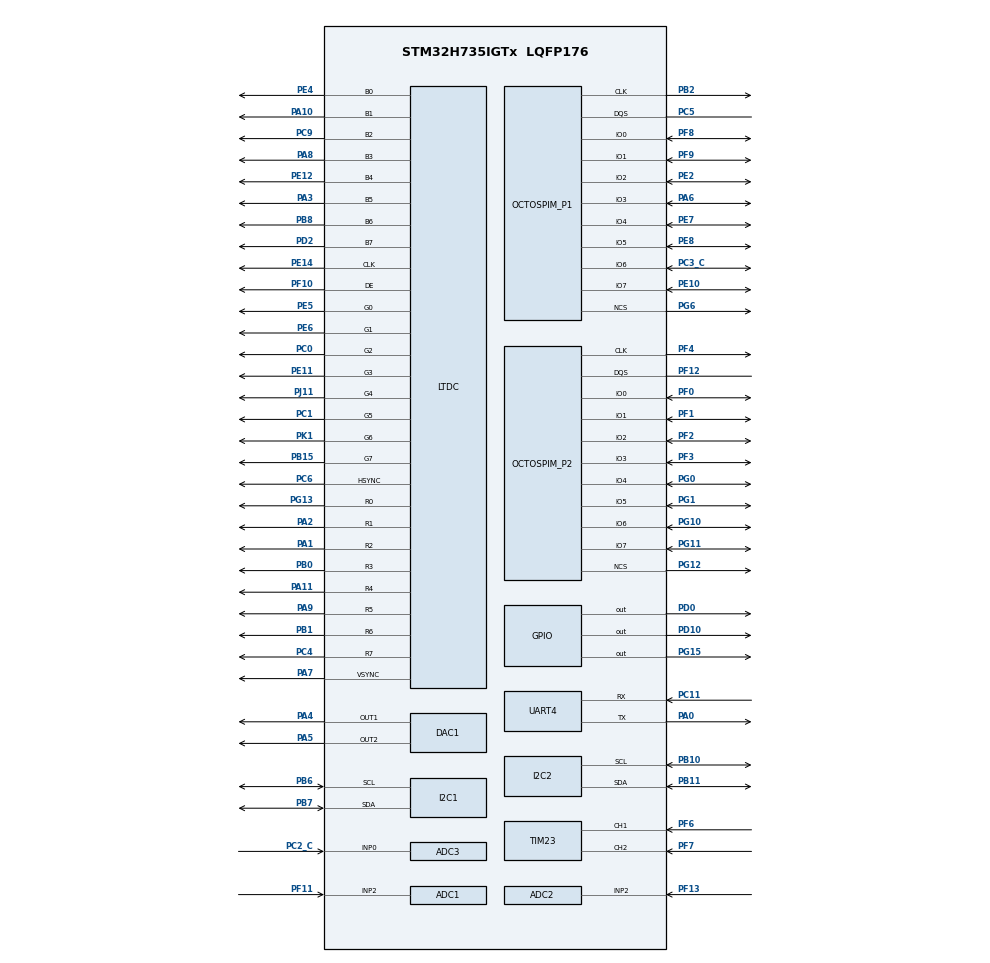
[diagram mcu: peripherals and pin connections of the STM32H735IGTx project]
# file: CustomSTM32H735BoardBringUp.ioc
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ADC1.Channel-0\#ChannelRegularConversion=ADC_CHANNEL_2
ADC1.ClockPrescaler=ADC_CLOCK_ASYNC_DIV4
ADC1.NbrOfConversionFlag=1
ADC1.OffsetNumber-0\#ChannelRegularConversion=ADC_OFFSET_NONE
ADC1.OffsetSignedSaturation-0\#ChannelRegularConversion=DISABLE
ADC1.Rank-0\#ChannelRegularConversion=1
ADC1.SamplingTime-0\#ChannelRegularConversion=ADC_SAMPLETIME_1CYCLE_5
ADC1.master=1
ADC2.Channel-0\#ChannelRegularConversion=ADC_CHANNEL_2
ADC2.ClockPrescaler=ADC_CLOCK_ASYNC_DIV4
ADC2.NbrOfConversionFlag=1
ADC2.OffsetNumber-0\#ChannelRegularConversion=ADC_OFFSET_NONE
ADC2.OffsetSignedSaturation-0\#ChannelRegularConversion=DISABLE
ADC2.Rank-0\#ChannelRegularConversion=1
ADC2.SamplingTime-0\#ChannelRegularConversion=ADC_SAMPLETIME_1CYCLE_5
ADC3.Channel-0\#ChannelRegularConversion=ADC_CHANNEL_0
ADC3.ClockPrescaler=ADC_CLOCK_ASYNC_DIV4
ADC3.NbrOfConversionFlag=1
ADC3.OffsetNumber-0\#ChannelRegularConversion=ADC_OFFSET_NONE
ADC3.OffsetSign-0\#ChannelRegularConversion=ADC3_OFFSET_SIGN_NEGATIVE
ADC3.Rank-0\#ChannelRegularConversion=1
ADC3.SamplingTime-0\#ChannelRegularConversion=ADC3_SAMPLETIME_2CYCLES_5
CORTEX_M7.AccessPermission-Cortex_Memory_Protection_Unit_Region0_Settings=MPU_REGION_FULL_ACCESS
CORTEX_M7.AccessPermission-Cortex_Memory_Protection_Unit_Region2_Settings=MPU_REGION_FULL_ACCESS
CORTEX_M7.AccessPermission-Cortex_Memory_Protection_Unit_Region4_Settings=MPU_REGION_FULL_ACCESS
CORTEX_M7.BaseAddress-Cortex_Memory_Protection_Unit_Region0_Settings=0x24000000
CORTEX_M7.BaseAddress-Cortex_Memory_Protection_Unit_Region1_Settings=0x70000000
CORTEX_M7.BaseAddress-Cortex_Memory_Protection_Unit_Region2_Settings=0x70000000
CORTEX_M7.BaseAddress-Cortex_Memory_Protection_Unit_Region3_Settings=0x90000000
CORTEX_M7.BaseAddress-Cortex_Memory_Protection_Unit_Region4_Settings=0x90000000
CORTEX_M7.CPU_DCache=Enabled
CORTEX_M7.CPU_ICache=Enabled
CORTEX_M7.DisableExec-Cortex_Memory_Protection_Unit_Region0_Settings=MPU_INSTRUCTION_ACCESS_DISABLE
CORTEX_M7.DisableExec-Cortex_Memory_Protection_Unit_Region1_Settings=MPU_INSTRUCTION_ACCESS_DISABLE
CORTEX_M7.DisableExec-Cortex_Memory_Protection_Unit_Region2_Settings=MPU_INSTRUCTION_ACCESS_DISABLE
CORTEX_M7.DisableExec-Cortex_Memory_Protection_Unit_Region3_Settings=MPU_INSTRUCTION_ACCESS_DISABLE
CORTEX_M7.DisableExec-Cortex_Memory_Protection_Unit_Region4_Settings=MPU_INSTRUCTION_ACCESS_DISABLE
CORTEX_M7.Enable-Cortex_Memory_Protection_Unit_Region0_Settings=MPU_REGION_ENABLE
CORTEX_M7.Enable-Cortex_Memory_Protection_Unit_Region1_Settings=MPU_REGION_ENABLE
CORTEX_M7.Enable-Cortex_Memory_Protection_Unit_Region2_Settings=MPU_REGION_ENABLE
CORTEX_M7.Enable-Cortex_Memory_Protection_Unit_Region3_Settings=MPU_REGION_ENABLE
CORTEX_M7.Enable-Cortex_Memory_Protection_Unit_Region4_Settings=MPU_REGION_ENABLE
CORTEX_M7.IsBufferable-Cortex_Memory_Protection_Unit_Region0_Settings=MPU_ACCESS_BUFFERABLE
CORTEX_M7.IsBufferable-Cortex_Memory_Protection_Unit_Region2_Settings=MPU_ACCESS_BUFFERABLE
CORTEX_M7.IsBufferable-Cortex_Memory_Protection_Unit_Region4_Settings=MPU_ACCESS_NOT_BUFFERABLE
CORTEX_M7.IsCacheable-Cortex_Memory_Protection_Unit_Region0_Settings=MPU_ACCESS_CACHEABLE
CORTEX_M7.IsCacheable-Cortex_Memory_Protection_Unit_Region2_Settings=MPU_ACCESS_CACHEABLE
CORTEX_M7.IsCacheable-Cortex_Memory_Protection_Unit_Region4_Settings=MPU_ACCESS_CACHEABLE
CORTEX_M7.MPU_Control=MPU_PRIVILEGED_DEFAULT
CORTEX_M7.Size-Cortex_Memory_Protection_Unit_Region0_Settings=MPU_REGION_SIZE_512KB
CORTEX_M7.Size-Cortex_Memory_Protection_Unit_Region1_Settings=MPU_REGION_SIZE_512MB
CORTEX_M7.Size-Cortex_Memory_Protection_Unit_Region2_Settings=MPU_REGION_SIZE_8MB
CORTEX_M7.Size-Cortex_Memory_Protection_Unit_Region3_Settings=MPU_REGION_SIZE_512MB
CORTEX_M7.Size-Cortex_Memory_Protection_Unit_Region4_Settings=MPU_REGION_SIZE_64MB
CORTEX_M7.default_mode_Activation=0
DAC1.DAC_Channel-DAC_OUT1=DAC_CHANNEL_1
DAC1.DAC_Channel-DAC_OUT2=DAC_CHANNEL_2
DMA2D.ColorMode=DMA2D_OUTPUT_RGB888
DMA2D.Mode=DMA2D_R2M
FREERTOS.Tasks01=defaultTask,24,1024,StartDefaultTask,Default,NULL,Dynamic,NULL,NULL;myTask02,8,1024,StartTask02,Default,NULL,Dynamic,NULL,NULL;TouchGFXTask,24,10000,TouchGFX_Task,As external,NULL,Dynamic,NULL,NULL
FREERTOS.configTOTAL_HEAP_SIZE=200000
FREERTOS.configUSE_NEWLIB_REENTRANT=1
I2C1.Timing=0x60404E72
I2C2.Timing=0x60404E72
LTDC.ActiveH=272
LTDC.ActiveW=480
LTDC.Alpha_L0=255
LTDC.FBStartAdress_L0=0x70000000
LTDC.HBP=13
LTDC.HFP=32
LTDC.HSync=41
LTDC.ImageHeight_L0=272
LTDC.ImageWidth_L0=480
LTDC.Layers=0
LTDC.PixelFormat_L0=LTDC_PIXEL_FORMAT_RGB888
LTDC.VSync=10
LTDC.WindowX1_L0=480
LTDC.WindowY1_L0=272
Mcu.Family=STM32H7
Mcu.Name=STM32H735IGTx
Mcu.Package=LQFP176
NVIC.LTDC_IRQn=true\:5\:0\:false\:false\:true\:true\:true\:true\:true
NVIC.PriorityGroup=NVIC_PRIORITYGROUP_4
NVIC.TIM6_DAC_IRQn=true\:15\:0\:false\:false\:true\:false\:false\:true\:true
NVIC.TimeBase=TIM6_DAC_IRQn
NVIC.TimeBaseIP=TIM6
OCTOSPI1.ChipSelectHighTime=2
OCTOSPI1.ClockPrescaler=2
OCTOSPI1.FifoThreshold=4
OCTOSPI1.MemoryType=HAL_OSPI_MEMTYPE_MACRONIX
OCTOSPI2.AccessTime=6
OCTOSPI2.ChipSelectBoundary=23
OCTOSPI2.ChipSelectHighTime=4
OCTOSPI2.ClockPrescaler=2
OCTOSPI2.DelayBlockBypass=HAL_OSPI_DELAY_BLOCK_USED
OCTOSPI2.DelayHoldQuarterCycle=HAL_OSPI_DHQC_ENABLE
OCTOSPI2.DeviceSize=24
OCTOSPI2.FifoThreshold=4
OCTOSPI2.LatencyMode=HAL_OSPI_FIXED_LATENCY
OCTOSPI2.RWRecoveryTime=3
OCTOSPI2.Refresh=400
OCTOSPI2.WriteZeroLatency=HAL_OSPI_LATENCY_ON_WRITE
PA0.Mode=Asynchronous
PA0.Signal=UART4_TX
PA1.Mode=RGB888
PA1.Signal=LTDC_R2
PA10.Mode=RGB888
PA10.Signal=LTDC_B1
PA11.Mode=RGB888
PA11.Signal=LTDC_R4
PA13(JTMS/SWDIO).Mode=Serial_Wire
PA13(JTMS/SWDIO).Signal=DEBUG_JTMS-SWDIO
PA14(JTCK/SWCLK).Mode=Serial_Wire
PA14(JTCK/SWCLK).Signal=DEBUG_JTCK-SWCLK
PA2.Mode=RGB888
PA2.Signal=LTDC_R1
PA3.Mode=RGB888
PA3.Signal=LTDC_B5
PA4.Signal=COMP_DAC11_group
PA5.Signal=COMP_DAC12_group
PA6.Mode=OCTOSPI1_IOL_Port1L
PA6.Signal=OCTOSPIM_P1_IO3
PA7.Mode=RGB888
PA7.Signal=LTDC_VSYNC
PA8.Mode=RGB888
PA8.Signal=LTDC_B3
PA9.Mode=RGB888
PA9.Signal=LTDC_R5
PB0.Mode=RGB888
PB0.Signal=LTDC_R3
PB1.Mode=RGB888
PB1.Signal=LTDC_R6
PB10.Mode=I2C
PB10.Signal=I2C2_SCL
PB11.Mode=I2C
PB11.Signal=I2C2_SDA
PB15.Mode=RGB888
PB15.Signal=LTDC_G7
PB2.Mode=O1_P1_CLK
PB2.Signal=OCTOSPIM_P1_CLK
PB6.Mode=I2C
PB6.Signal=I2C1_SCL
PB7.Mode=I2C
PB7.Signal=I2C1_SDA
PB8.Mode=RGB888
PB8.Signal=LTDC_B6
PC0.Mode=RGB888
PC0.Signal=LTDC_G2
PC1.Mode=RGB888
PC1.Signal=LTDC_G5
PC11.Mode=Asynchronous
PC11.Signal=UART4_RX
PC2_C.Mode=IN0-Single-Ended
PC2_C.Signal=ADC3_INP0
PC3_C.Mode=OCTOSPI1_IOH_Port1H
PC3_C.Signal=OCTOSPIM_P1_IO6
PC4.Mode=RGB888
PC4.Signal=LTDC_R7
PC5.Mode=OCTOSPI1_Port1_DQS
PC5.Signal=OCTOSPIM_P1_DQS
PC6.Mode=RGB888
PC6.Signal=LTDC_HSYNC
PC9.Mode=RGB888
PC9.Signal=LTDC_B2
PD0.Signal=GPIO_Output
PD10.Signal=GPIO_Output
PD2.Mode=RGB888
PD2.Signal=LTDC_B7
PE10.Mode=OCTOSPI1_IOH_Port1H
PE10.Signal=OCTOSPIM_P1_IO7
PE11.Mode=RGB888
PE11.Signal=LTDC_G3
PE12.Mode=RGB888
PE12.Signal=LTDC_B4
PE14.Mode=RGB888
PE14.Signal=LTDC_CLK
PE2.Mode=OCTOSPI1_IOL_Port1L
PE2.Signal=OCTOSPIM_P1_IO2
PE4.Mode=RGB888
PE4.Signal=LTDC_B0
PE5.Mode=RGB888
PE5.Signal=LTDC_G0
PE6.Mode=RGB888
PE6.Signal=LTDC_G1
PE7.Mode=OCTOSPI1_IOH_Port1H
PE7.Signal=OCTOSPIM_P1_IO4
PE8.Mode=OCTOSPI1_IOH_Port1H
PE8.Signal=OCTOSPIM_P1_IO5
PF0.Mode=OCTOSPI2_IOL_Port2L
PF0.Signal=OCTOSPIM_P2_IO0
PF1.Mode=OCTOSPI2_IOL_Port2L
PF1.Signal=OCTOSPIM_P2_IO1
PF10.Mode=RGB888
PF10.Signal=LTDC_DE
PF11.Mode=IN2-Single-Ended
PF11.Signal=ADC1_INP2
PF12.Mode=OCTOSPI2_Port2_DQS
PF12.Signal=OCTOSPIM_P2_DQS
PF13.Mode=IN2-Single-Ended
PF13.Signal=ADC2_INP2
PF2.Mode=OCTOSPI2_IOL_Port2L
PF2.Signal=OCTOSPIM_P2_IO2
PF3.Mode=OCTOSPI2_IOL_Port2L
PF3.Signal=OCTOSPIM_P2_IO3
PF4.Mode=O2_P2_CLK
PF4.Signal=OCTOSPIM_P2_CLK
PF6.Mode=Encoder_Interface
PF6.Signal=TIM23_CH1
PF7.Signal=S_TIM23_CH2
PF8.Mode=OCTOSPI1_IOL_Port1L
PF8.Signal=OCTOSPIM_P1_IO0
PF9.Mode=OCTOSPI1_IOL_Port1L
PF9.Signal=OCTOSPIM_P1_IO1
PG0.Mode=OCTOSPI2_IOH_Port2H
PG0.Signal=OCTOSPIM_P2_IO4
PG1.Mode=OCTOSPI2_IOH_Port2H
PG1.Signal=OCTOSPIM_P2_IO5
PG10.Mode=OCTOSPI2_IOH_Port2H
PG10.Signal=OCTOSPIM_P2_IO6
PG11.Mode=OCTOSPI2_IOH_Port2H
PG11.Signal=OCTOSPIM_P2_IO7
PG12.Mode=OCTOSPI2_Port2_NCS
PG12.Signal=OCTOSPIM_P2_NCS
PG13.Mode=RGB888
PG13.Signal=LTDC_R0
PG15.Signal=GPIO_Output
PG6.Mode=OCTOSPI1_Port1_NCS
PG6.Signal=OCTOSPIM_P1_NCS
PH0-OSC_IN.Mode=HSE-External-Oscillator
PH0-OSC_IN.Signal=RCC_OSC_IN
PH1-OSC_OUT.Mode=HSE-External-Oscillator
PH1-OSC_OUT.Signal=RCC_OSC_OUT
PJ11.Mode=RGB888
PJ11.Signal=LTDC_G4
PK1.Mode=RGB888
PK1.Signal=LTDC_G6
ProjectManager.HeapSize=0x200
ProjectManager.StackSize=0x400
ProjectManager.TargetToolchain=STM32CubeIDE
RCC.ADCCLockSelection=RCC_ADCCLKSOURCE_CLKP
RCC.ADCFreq_Value=64000000
RCC.APB1Freq_Value=137500000
RCC.APB2Freq_Value=137500000
RCC.APB3Freq_Value=137500000
RCC.APB4Freq_Value=137500000
RCC.CortexFreq_Value=550000000
RCC.D1PPRE=RCC_APB3_DIV2
RCC.D2PPRE1=RCC_APB1_DIV2
RCC.D2PPRE2=RCC_APB2_DIV2
RCC.D3PPRE=RCC_APB4_DIV2
RCC.DIVM1=2
RCC.DIVM2=5
RCC.DIVM3=25
RCC.DIVN1=44
RCC.DIVN2=80
RCC.DIVN3=288
RCC.DIVP1=1
RCC.DIVR3=30
RCC.HCLKFreq_Value=275000000
RCC.HPRE=RCC_HCLK_DIV2
RCC.PLL2FRACN=0
RCC.PLL3FRACN=0
RCC.PLLFRACN=0
RCC.PLLSourceVirtual=RCC_PLLSOURCE_HSE
RCC.QSPICLockSelection=RCC_OSPICLKSOURCE_PLL2
RCC.SYSCLKFreq_VALUE=550000000
RCC.SYSCLKSource=RCC_SYSCLKSOURCE_PLLCLK
RCC.USBFreq_Value=275000000
SH.COMP_DAC11_group.0=DAC1_OUT1,DAC_OUT1
SH.COMP_DAC12_group.0=DAC1_OUT2,DAC_OUT2
SH.S_TIM23_CH2.0=TIM23_CH2,Encoder_Interface
STMicroelectronics.X-CUBE-TOUCHGFX.4.24.0.ApplicationCcGraphicsJjApplication=TouchGFXOoGenerator
STMicroelectronics.X-CUBE-TOUCHGFX.4.24.0.tgfx_address1=0x70000000
STMicroelectronics.X-CUBE-TOUCHGFX.4.24.0.tgfx_address2=0x70200000
STMicroelectronics.X-CUBE-TOUCHGFX.4.24.0.tgfx_buffering_strategy=Double
STMicroelectronics.X-CUBE-TOUCHGFX.4.24.0.tgfx_display_interface=disp_ltdc
STMicroelectronics.X-CUBE-TOUCHGFX.4.24.0.tgfx_hardware_accelerator=dma_2d
STMicroelectronics.X-CUBE-TOUCHGFX.4.24.0.tgfx_location=Allocate
STMicroelectronics.X-CUBE-TOUCHGFX.4.24.0.tgfx_vector_fonts=Enabled
STMicroelectronics.X-CUBE-TOUCHGFX.4.24.0.tgfx_vector_rendering=Software
STMicroelectronics.X-CUBE-TOUCHGFX.4.24.0.tgfx_video=Disabled
STMicroelectronics.X-CUBE-TOUCHGFX.4.24.0.tgfx_video_buffer_format=RGB888\:3
STMicroelectronics.X-CUBE-TOUCHGFX.4.24.0.tgfx_video_height=272
STMicroelectronics.X-CUBE-TOUCHGFX.4.24.0.tgfx_video_strategy=1
STMicroelectronics.X-CUBE-TOUCHGFX.4.24.0.tgfx_video_width=480
STMicroelectronics.X-CUBE-TOUCHGFX.4.24.0.tgfx_vsync=vsync_ltdc
STMicroelectronics.X-CUBE-TOUCHGFX.4.24.0_IsPackSelfContextualization=true
VP_CRC_VS_CRC.Mode=CRC_Activate
VP_DMA2D_VS_DMA2D.Mode=DMA2D_Activate
VP_FREERTOS_VS_CMSIS_V2.Mode=CMSIS_V2
VP_LIBJPEG_VS_JPEGLIB.Mode=Enabled
VP_MEMORYMAP_VS_MEMORYMAP.Mode=CurAppReg
VP_OCTOSPI1_VS_octo.Mode=octo_mode
VP_OCTOSPI2_VS_octo.Mode=hyperbus_mode
VP_STMicroelectronics.X-CUBE-TOUCHGFX_VS_GraphicsJjApplication_4.24.0.Mode=GraphicsJjApplication
VP_SYS_VS_tim6.Mode=TIM6
VP_TIM1_VS_ClockSourceITR.Mode=TriggerSource_ITR0
board=custom

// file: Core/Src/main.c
/* USER CODE BEGIN Header */
/**
 ******************************************************************************
 * @file           : main.c
 * @brief          : Main program body
 ******************************************************************************
 * @attention
 *
 * Copyright (c) 2024 STMicroelectronics.
 * All rights reserved.
 *
 * This software is licensed under terms that can be found in the LICENSE file
 * in the root directory of this software component.
 * If no LICENSE file comes with this software, it is provided AS-IS.
 *
 ******************************************************************************
 */
/* USER CODE END Header */
#include "main.h"
#include "cmsis_os.h"
#include "libjpeg.h"
#include "app_touchgfx.h"

/* USER CODE BEGIN Includes */
#include "stm32h735g_discovery_ospi.h"
#include "stm32h7xx_hal_ospi.h"
#include "stm32h735g_discovery_ts.h"
#include "stm32h735g_discovery_bus.h"
/* USER CODE END Includes */

ADC_HandleTypeDef hadc1;
ADC_HandleTypeDef hadc2;
ADC_HandleTypeDef hadc3;

CRC_HandleTypeDef hcrc;

DAC_HandleTypeDef hdac1;

DMA2D_HandleTypeDef hdma2d;

I2C_HandleTypeDef hi2c1;
I2C_HandleTypeDef hi2c2;

LTDC_HandleTypeDef hltdc;

OSPI_HandleTypeDef hospi1;
OSPI_HandleTypeDef hospi2;

TIM_HandleTypeDef htim1;
TIM_HandleTypeDef htim23;

UART_HandleTypeDef huart4;

/* Definitions for defaultTask */
osThreadId_t defaultTaskHandle;
const osThreadAttr_t defaultTask_attributes = {
  .name = "defaultTask",
  .stack_size = 1024 * 4,
  .priority = (osPriority_t) osPriorityNormal,
};
/* Definitions for myTask02 */
osThreadId_t myTask02Handle;
const osThreadAttr_t myTask02_attributes = {
  .name = "myTask02",
  .stack_size = 1024 * 4,
  .priority = (osPriority_t) osPriorityLow,
};
/* Definitions for TouchGFXTask */
osThreadId_t TouchGFXTaskHandle;
const osThreadAttr_t TouchGFXTask_attributes = {
  .name = "TouchGFXTask",
  .stack_size = 10000 * 4,
  .priority = (osPriority_t) osPriorityNormal,
};
/* USER CODE BEGIN PV */
uint32_t counter = 0;
uint32_t *externalFlash = 0x90000000;
const uint32_t size = 1000;
uint32_t result[1000];
uint8_t test[46880];
MX25LM51245G_Info_t infoFlash;
int32_t FTprobe;

/* USER CODE END PV */

void SystemClock_Config(void);
void PeriphCommonClock_Config(void);
static void MPU_Config(void);
static void MX_GPIO_Init(void);
static void MX_ADC1_Init(void);
static void MX_ADC2_Init(void);
static void MX_ADC3_Init(void);
static void MX_CRC_Init(void);
static void MX_DAC1_Init(void);
static void MX_DMA2D_Init(void);
static void MX_I2C1_Init(void);
static void MX_I2C2_Init(void);
static void MX_LTDC_Init(void);
static void MX_OCTOSPI1_Init(void);
static void MX_OCTOSPI2_Init(void);
static void MX_TIM1_Init(void);
static void MX_TIM23_Init(void);
static void MX_UART4_Init(void);
void StartDefaultTask(void *argument);
void StartTask02(void *argument);
extern void TouchGFX_Task(void *argument);

int main(void)
{

  /* MPU Configuration--------------------------------------------------------*/
  MPU_Config();

  /* Enable the CPU Cache */

  /* Enable I-Cache---------------------------------------------------------*/
  SCB_EnableICache();

  /* Enable D-Cache---------------------------------------------------------*/
  SCB_EnableDCache();

  /* MCU Configuration--------------------------------------------------------*/

  /* Reset of all peripherals, Initializes the Flash interface and the Systick. */
  HAL_Init();

  /* Configure the system clock */
  SystemClock_Config();

  /* Configure the peripherals common clocks */
  PeriphCommonClock_Config();

  /* Initialize all configured peripherals */
  MX_GPIO_Init();
  MX_ADC1_Init();
  MX_ADC2_Init();
  MX_ADC3_Init();
  MX_CRC_Init();
  MX_DAC1_Init();
  MX_DMA2D_Init();
  MX_I2C1_Init();
  MX_I2C2_Init();
  MX_LTDC_Init();
  MX_LIBJPEG_Init();
  MX_OCTOSPI1_Init();
  MX_OCTOSPI2_Init();
  MX_TIM1_Init();
  MX_TIM23_Init();
  MX_UART4_Init();
  MX_TouchGFX_Init();
  /* Call PreOsInit function */
  MX_TouchGFX_PreOSInit();
  /* USER CODE BEGIN 2 */

//	HAL_GPIO_WritePin(GPIOD, GPIO_PIN_10, GPIO_PIN_SET);//enable LCD
//	HAL_GPIO_WritePin(GPIOG, GPIO_PIN_15, GPIO_PIN_SET); //turn display backlight on
//	HAL_GPIO_WritePin(GPIOD, GPIO_PIN_0, GPIO_PIN_RESET); //reset LCD
//	HAL_GPIO_WritePin(GPIOD, GPIO_PIN_0, GPIO_PIN_SET); //reset LCD
	HAL_SYSCFG_AnalogSwitchConfig(SYSCFG_SWITCH_PC3,SYSCFG_SWITCH_PC3_CLOSE); //connects PC3_C with PC3
	//FTprobe = FT5336_Probe();
  /* USER CODE END 2 */

  /* Init scheduler */
  osKernelInitialize();

  /* Create the thread(s) */
  /* creation of defaultTask */
  defaultTaskHandle = osThreadNew(StartDefaultTask, NULL, &defaultTask_attributes);

  /* creation of myTask02 */
  myTask02Handle = osThreadNew(StartTask02, NULL, &myTask02_attributes);

  /* creation of TouchGFXTask */
  TouchGFXTaskHandle = osThreadNew(TouchGFX_Task, NULL, &TouchGFXTask_attributes);

  /* Start scheduler */
  osKernelStart();

  /* We should never get here as control is now taken by the scheduler */

  /* Infinite loop */
	while (1)
	{

	}
}

void SystemClock_Config(void)
{
  RCC_OscInitTypeDef RCC_OscInitStruct = {0};
  RCC_ClkInitTypeDef RCC_ClkInitStruct = {0};

  /** Supply configuration update enable
  */
  HAL_PWREx_ConfigSupply(PWR_DIRECT_SMPS_SUPPLY);

  /** Configure the main internal regulator output voltage
  */
  __HAL_PWR_VOLTAGESCALING_CONFIG(PWR_REGULATOR_VOLTAGE_SCALE0);

  while(!__HAL_PWR_GET_FLAG(PWR_FLAG_VOSRDY)) {}

  /** Initializes the RCC Oscillators according to the specified parameters
  * in the RCC_OscInitTypeDef structure.
  */
  RCC_OscInitStruct.OscillatorType = RCC_OSCILLATORTYPE_HSI|RCC_OSCILLATORTYPE_HSE;
  RCC_OscInitStruct.HSEState = RCC_HSE_ON;
  RCC_OscInitStruct.HSIState = RCC_HSI_DIV1;
  RCC_OscInitStruct.HSICalibrationValue = 64;
  RCC_OscInitStruct.PLL.PLLState = RCC_PLL_ON;
  RCC_OscInitStruct.PLL.PLLSource = RCC_PLLSOURCE_HSE;
  RCC_OscInitStruct.PLL.PLLM = 2;
  RCC_OscInitStruct.PLL.PLLN = 44;
  RCC_OscInitStruct.PLL.PLLP = 1;
  RCC_OscInitStruct.PLL.PLLQ = 2;
  RCC_OscInitStruct.PLL.PLLR = 2;
  RCC_OscInitStruct.PLL.PLLRGE = RCC_PLL1VCIRANGE_3;
  RCC_OscInitStruct.PLL.PLLVCOSEL = RCC_PLL1VCOWIDE;
  RCC_OscInitStruct.PLL.PLLFRACN = 0;
  if (HAL_RCC_OscConfig(&RCC_OscInitStruct) != HAL_OK)
  {
    Error_Handler();
  }

  /** Initializes the CPU, AHB and APB buses clocks
  */
  RCC_ClkInitStruct.ClockType = RCC_CLOCKTYPE_HCLK|RCC_CLOCKTYPE_SYSCLK
                              |RCC_CLOCKTYPE_PCLK1|RCC_CLOCKTYPE_PCLK2
                              |RCC_CLOCKTYPE_D3PCLK1|RCC_CLOCKTYPE_D1PCLK1;
  RCC_ClkInitStruct.SYSCLKSource = RCC_SYSCLKSOURCE_PLLCLK;
  RCC_ClkInitStruct.SYSCLKDivider = RCC_SYSCLK_DIV1;
  RCC_ClkInitStruct.AHBCLKDivider = RCC_HCLK_DIV2;
  RCC_ClkInitStruct.APB3CLKDivider = RCC_APB3_DIV2;
  RCC_ClkInitStruct.APB1CLKDivider = RCC_APB1_DIV2;
  RCC_ClkInitStruct.APB2CLKDivider = RCC_APB2_DIV2;
  RCC_ClkInitStruct.APB4CLKDivider = RCC_APB4_DIV2;

  if (HAL_RCC_ClockConfig(&RCC_ClkInitStruct, FLASH_LATENCY_3) != HAL_OK)
  {
    Error_Handler();
  }
}

void PeriphCommonClock_Config(void)
{
  RCC_PeriphCLKInitTypeDef PeriphClkInitStruct = {0};

  /** Initializes the peripherals clock
  */
  PeriphClkInitStruct.PeriphClockSelection = RCC_PERIPHCLK_OSPI|RCC_PERIPHCLK_CKPER;
  PeriphClkInitStruct.PLL2.PLL2M = 5;
  PeriphClkInitStruct.PLL2.PLL2N = 80;
  PeriphClkInitStruct.PLL2.PLL2P = 2;
  PeriphClkInitStruct.PLL2.PLL2Q = 2;
  PeriphClkInitStruct.PLL2.PLL2R = 2;
  PeriphClkInitStruct.PLL2.PLL2RGE = RCC_PLL2VCIRANGE_2;
  PeriphClkInitStruct.PLL2.PLL2VCOSEL = RCC_PLL2VCOWIDE;
  PeriphClkInitStruct.PLL2.PLL2FRACN = 0;
  PeriphClkInitStruct.OspiClockSelection = RCC_OSPICLKSOURCE_PLL2;
  PeriphClkInitStruct.CkperClockSelection = RCC_CLKPSOURCE_HSI;
  if (HAL_RCCEx_PeriphCLKConfig(&PeriphClkInitStruct) != HAL_OK)
  {
    Error_Handler();
  }
}

static void MX_ADC1_Init(void)
{

  ADC_MultiModeTypeDef multimode = {0};
  ADC_ChannelConfTypeDef sConfig = {0};

  /** Common config
  */
  hadc1.Instance = ADC1;
  hadc1.Init.ClockPrescaler = ADC_CLOCK_ASYNC_DIV4;
  hadc1.Init.Resolution = ADC_RESOLUTION_16B;
  hadc1.Init.ScanConvMode = ADC_SCAN_DISABLE;
  hadc1.Init.EOCSelection = ADC_EOC_SINGLE_CONV;
  hadc1.Init.LowPowerAutoWait = DISABLE;
  hadc1.Init.ContinuousConvMode = DISABLE;
  hadc1.Init.NbrOfConversion = 1;
  hadc1.Init.DiscontinuousConvMode = DISABLE;
  hadc1.Init.ExternalTrigConv = ADC_SOFTWARE_START;
  hadc1.Init.ExternalTrigConvEdge = ADC_EXTERNALTRIGCONVEDGE_NONE;
  hadc1.Init.ConversionDataManagement = ADC_CONVERSIONDATA_DR;
  hadc1.Init.Overrun = ADC_OVR_DATA_PRESERVED;
  hadc1.Init.LeftBitShift = ADC_LEFTBITSHIFT_NONE;
  hadc1.Init.OversamplingMode = DISABLE;
  hadc1.Init.Oversampling.Ratio = 1;
  if (HAL_ADC_Init(&hadc1) != HAL_OK)
  {
    Error_Handler();
  }

  /** Configure the ADC multi-mode
  */
  multimode.Mode = ADC_MODE_INDEPENDENT;
  if (HAL_ADCEx_MultiModeConfigChannel(&hadc1, &multimode) != HAL_OK)
  {
    Error_Handler();
  }

  /** Configure Regular Channel
  */
  sConfig.Channel = ADC_CHANNEL_2;
  sConfig.Rank = ADC_REGULAR_RANK_1;
  sConfig.SamplingTime = ADC_SAMPLETIME_1CYCLE_5;
  sConfig.SingleDiff = ADC_SINGLE_ENDED;
  sConfig.OffsetNumber = ADC_OFFSET_NONE;
  sConfig.Offset = 0;
  sConfig.OffsetSignedSaturation = DISABLE;
  if (HAL_ADC_ConfigChannel(&hadc1, &sConfig) != HAL_OK)
  {
    Error_Handler();
  }

}

static void MX_ADC2_Init(void)
{

  ADC_ChannelConfTypeDef sConfig = {0};

  /** Common config
  */
  hadc2.Instance = ADC2;
  hadc2.Init.ClockPrescaler = ADC_CLOCK_ASYNC_DIV4;
  hadc2.Init.Resolution = ADC_RESOLUTION_16B;
  hadc2.Init.ScanConvMode = ADC_SCAN_DISABLE;
  hadc2.Init.EOCSelection = ADC_EOC_SINGLE_CONV;
  hadc2.Init.LowPowerAutoWait = DISABLE;
  hadc2.Init.ContinuousConvMode = DISABLE;
  hadc2.Init.NbrOfConversion = 1;
  hadc2.Init.DiscontinuousConvMode = DISABLE;
  hadc2.Init.ExternalTrigConv = ADC_SOFTWARE_START;
  hadc2.Init.ExternalTrigConvEdge = ADC_EXTERNALTRIGCONVEDGE_NONE;
  hadc2.Init.ConversionDataManagement = ADC_CONVERSIONDATA_DR;
  hadc2.Init.Overrun = ADC_OVR_DATA_PRESERVED;
  hadc2.Init.LeftBitShift = ADC_LEFTBITSHIFT_NONE;
  hadc2.Init.OversamplingMode = DISABLE;
  hadc2.Init.Oversampling.Ratio = 1;
  if (HAL_ADC_Init(&hadc2) != HAL_OK)
  {
    Error_Handler();
  }

  /** Configure Regular Channel
  */
  sConfig.Channel = ADC_CHANNEL_2;
  sConfig.Rank = ADC_REGULAR_RANK_1;
  sConfig.SamplingTime = ADC_SAMPLETIME_1CYCLE_5;
  sConfig.SingleDiff = ADC_SINGLE_ENDED;
  sConfig.OffsetNumber = ADC_OFFSET_NONE;
  sConfig.Offset = 0;
  sConfig.OffsetSignedSaturation = DISABLE;
  if (HAL_ADC_ConfigChannel(&hadc2, &sConfig) != HAL_OK)
  {
    Error_Handler();
  }

}

static void MX_ADC3_Init(void)
{

  ADC_ChannelConfTypeDef sConfig = {0};

  /** Common config
  */
  hadc3.Instance = ADC3;
  hadc3.Init.ClockPrescaler = ADC_CLOCK_ASYNC_DIV1;
  hadc3.Init.Resolution = ADC_RESOLUTION_12B;
  hadc3.Init.DataAlign = ADC3_DATAALIGN_RIGHT;
  hadc3.Init.ScanConvMode = ADC_SCAN_DISABLE;
  hadc3.Init.EOCSelection = ADC_EOC_SINGLE_CONV;
  hadc3.Init.LowPowerAutoWait = DISABLE;
  hadc3.Init.ContinuousConvMode = DISABLE;
  hadc3.Init.NbrOfConversion = 1;
  hadc3.Init.DiscontinuousConvMode = DISABLE;
  hadc3.Init.ExternalTrigConv = ADC_SOFTWARE_START;
  hadc3.Init.ExternalTrigConvEdge = ADC_EXTERNALTRIGCONVEDGE_NONE;
  hadc3.Init.DMAContinuousRequests = DISABLE;
  hadc3.Init.SamplingMode = ADC_SAMPLING_MODE_NORMAL;
  hadc3.Init.ConversionDataManagement = ADC_CONVERSIONDATA_DR;
  hadc3.Init.Overrun = ADC_OVR_DATA_PRESERVED;
  hadc3.Init.LeftBitShift = ADC_LEFTBITSHIFT_NONE;
  hadc3.Init.OversamplingMode = DISABLE;
  hadc3.Init.Oversampling.Ratio = ADC3_OVERSAMPLING_RATIO_2;
  if (HAL_ADC_Init(&hadc3) != HAL_OK)
  {
    Error_Handler();
  }

  /** Configure Regular Channel
  */
  sConfig.Channel = ADC_CHANNEL_0;
  sConfig.Rank = ADC_REGULAR_RANK_1;
  sConfig.SamplingTime = ADC3_SAMPLETIME_2CYCLES_5;
  sConfig.SingleDiff = ADC_SINGLE_ENDED;
  sConfig.OffsetNumber = ADC_OFFSET_NONE;
  sConfig.Offset = 0;
  sConfig.OffsetSign = ADC3_OFFSET_SIGN_NEGATIVE;
  if (HAL_ADC_ConfigChannel(&hadc3, &sConfig) != HAL_OK)
  {
    Error_Handler();
  }

}

static void MX_CRC_Init(void)
{

  hcrc.Instance = CRC;
  hcrc.Init.DefaultPolynomialUse = DEFAULT_POLYNOMIAL_ENABLE;
  hcrc.Init.DefaultInitValueUse = DEFAULT_INIT_VALUE_ENABLE;
  hcrc.Init.InputDataInversionMode = CRC_INPUTDATA_INVERSION_NONE;
  hcrc.Init.OutputDataInversionMode = CRC_OUTPUTDATA_INVERSION_DISABLE;
  hcrc.InputDataFormat = CRC_INPUTDATA_FORMAT_BYTES;
  if (HAL_CRC_Init(&hcrc) != HAL_OK)
  {
    Error_Handler();
  }

}

static void MX_DAC1_Init(void)
{

  DAC_ChannelConfTypeDef sConfig = {0};

  /** DAC Initialization
  */
  hdac1.Instance = DAC1;
  if (HAL_DAC_Init(&hdac1) != HAL_OK)
  {
    Error_Handler();
  }

  /** DAC channel OUT1 config
  */
  sConfig.DAC_SampleAndHold = DAC_SAMPLEANDHOLD_DISABLE;
  sConfig.DAC_Trigger = DAC_TRIGGER_NONE;
  sConfig.DAC_OutputBuffer = DAC_OUTPUTBUFFER_ENABLE;
  sConfig.DAC_ConnectOnChipPeripheral = DAC_CHIPCONNECT_DISABLE;
  sConfig.DAC_UserTrimming = DAC_TRIMMING_FACTORY;
  if (HAL_DAC_ConfigChannel(&hdac1, &sConfig, DAC_CHANNEL_1) != HAL_OK)
  {
    Error_Handler();
  }

  /** DAC channel OUT2 config
  */
  if (HAL_DAC_ConfigChannel(&hdac1, &sConfig, DAC_CHANNEL_2) != HAL_OK)
  {
    Error_Handler();
  }

}

static void MX_DMA2D_Init(void)
{

  hdma2d.Instance = DMA2D;
  hdma2d.Init.Mode = DMA2D_R2M;
  hdma2d.Init.ColorMode = DMA2D_OUTPUT_RGB888;
  hdma2d.Init.OutputOffset = 0;
  if (HAL_DMA2D_Init(&hdma2d) != HAL_OK)
  {
    Error_Handler();
  }

}

static void MX_I2C1_Init(void)
{

  hi2c1.Instance = I2C1;
  hi2c1.Init.Timing = 0x60404E72;
  hi2c1.Init.OwnAddress1 = 0;
  hi2c1.Init.AddressingMode = I2C_ADDRESSINGMODE_7BIT;
  hi2c1.Init.DualAddressMode = I2C_DUALADDRESS_DISABLE;
  hi2c1.Init.OwnAddress2 = 0;
  hi2c1.Init.OwnAddress2Masks = I2C_OA2_NOMASK;
  hi2c1.Init.GeneralCallMode = I2C_GENERALCALL_DISABLE;
  hi2c1.Init.NoStretchMode = I2C_NOSTRETCH_DISABLE;
  if (HAL_I2C_Init(&hi2c1) != HAL_OK)
  {
    Error_Handler();
  }

  /** Configure Analogue filter
  */
  if (HAL_I2CEx_ConfigAnalogFilter(&hi2c1, I2C_ANALOGFILTER_ENABLE) != HAL_OK)
  {
    Error_Handler();
  }

  /** Configure Digital filter
  */
  if (HAL_I2CEx_ConfigDigitalFilter(&hi2c1, 0) != HAL_OK)
  {
    Error_Handler();
  }

}

static void MX_I2C2_Init(void)
{

  hi2c2.Instance = I2C2;
  hi2c2.Init.Timing = 0x60404E72;
  hi2c2.Init.OwnAddress1 = 0;
  hi2c2.Init.AddressingMode = I2C_ADDRESSINGMODE_7BIT;
  hi2c2.Init.DualAddressMode = I2C_DUALADDRESS_DISABLE;
  hi2c2.Init.OwnAddress2 = 0;
  hi2c2.Init.OwnAddress2Masks = I2C_OA2_NOMASK;
  hi2c2.Init.GeneralCallMode = I2C_GENERALCALL_DISABLE;
  hi2c2.Init.NoStretchMode = I2C_NOSTRETCH_DISABLE;
  if (HAL_I2C_Init(&hi2c2) != HAL_OK)
  {
    Error_Handler();
  }

  /** Configure Analogue filter
  */
  if (HAL_I2CEx_ConfigAnalogFilter(&hi2c2, I2C_ANALOGFILTER_ENABLE) != HAL_OK)
  {
    Error_Handler();
  }

  /** Configure Digital filter
  */
  if (HAL_I2CEx_ConfigDigitalFilter(&hi2c2, 0) != HAL_OK)
  {
    Error_Handler();
  }

}

static void MX_LTDC_Init(void)
{

  LTDC_LayerCfgTypeDef pLayerCfg = {0};

  hltdc.Instance = LTDC;
  hltdc.Init.HSPolarity = LTDC_HSPOLARITY_AL;
  hltdc.Init.VSPolarity = LTDC_VSPOLARITY_AL;
  hltdc.Init.DEPolarity = LTDC_DEPOLARITY_AL;
  hltdc.Init.PCPolarity = LTDC_PCPOLARITY_IPC;
  hltdc.Init.HorizontalSync = 40;
  hltdc.Init.VerticalSync = 9;
  hltdc.Init.AccumulatedHBP = 53;
  hltdc.Init.AccumulatedVBP = 11;
  hltdc.Init.AccumulatedActiveW = 533;
  hltdc.Init.AccumulatedActiveH = 283;
  hltdc.Init.TotalWidth = 565;
  hltdc.Init.TotalHeigh = 285;
  hltdc.Init.Backcolor.Blue = 0;
  hltdc.Init.Backcolor.Green = 0;
  hltdc.Init.Backcolor.Red = 0;
  if (HAL_LTDC_Init(&hltdc) != HAL_OK)
  {
    Error_Handler();
  }
  pLayerCfg.WindowX0 = 0;
  pLayerCfg.WindowX1 = 480;
  pLayerCfg.WindowY0 = 0;
  pLayerCfg.WindowY1 = 272;
  pLayerCfg.PixelFormat = LTDC_PIXEL_FORMAT_RGB888;
  pLayerCfg.Alpha = 255;
  pLayerCfg.Alpha0 = 0;
  pLayerCfg.BlendingFactor1 = LTDC_BLENDING_FACTOR1_CA;
  pLayerCfg.BlendingFactor2 = LTDC_BLENDING_FACTOR2_CA;
  pLayerCfg.FBStartAdress = 0x70000000;
  pLayerCfg.ImageWidth = 480;
  pLayerCfg.ImageHeight = 272;
  pLayerCfg.Backcolor.Blue = 0;
  pLayerCfg.Backcolor.Green = 0;
  pLayerCfg.Backcolor.Red = 0;
  if (HAL_LTDC_ConfigLayer(&hltdc, &pLayerCfg, 0) != HAL_OK)
  {
    Error_Handler();
  }

}

static void MX_OCTOSPI1_Init(void)
{

  /* USER CODE BEGIN OCTOSPI1_Init 0 */
	BSP_OSPI_NOR_Init_t ospi_nor_int;
  /* USER CODE END OCTOSPI1_Init 0 */

  OSPIM_CfgTypeDef sOspiManagerCfg = {0};

  /* OCTOSPI1 parameter configuration*/
  hospi1.Instance = OCTOSPI1;
  hospi1.Init.FifoThreshold = 4;
  hospi1.Init.DualQuad = HAL_OSPI_DUALQUAD_DISABLE;
  hospi1.Init.MemoryType = HAL_OSPI_MEMTYPE_MACRONIX;
  hospi1.Init.DeviceSize = 32;
  hospi1.Init.ChipSelectHighTime = 2;
  hospi1.Init.FreeRunningClock = HAL_OSPI_FREERUNCLK_DISABLE;
  hospi1.Init.ClockMode = HAL_OSPI_CLOCK_MODE_0;
  hospi1.Init.WrapSize = HAL_OSPI_WRAP_NOT_SUPPORTED;
  hospi1.Init.ClockPrescaler = 2;
  hospi1.Init.SampleShifting = HAL_OSPI_SAMPLE_SHIFTING_NONE;
  hospi1.Init.DelayHoldQuarterCycle = HAL_OSPI_DHQC_DISABLE;
  hospi1.Init.ChipSelectBoundary = 0;
  hospi1.Init.DelayBlockBypass = HAL_OSPI_DELAY_BLOCK_BYPASSED;
  hospi1.Init.MaxTran = 0;
  hospi1.Init.Refresh = 0;
  if (HAL_OSPI_Init(&hospi1) != HAL_OK)
  {
    Error_Handler();
  }
  sOspiManagerCfg.ClkPort = 1;
  sOspiManagerCfg.DQSPort = 1;
  sOspiManagerCfg.NCSPort = 1;
  sOspiManagerCfg.IOLowPort = HAL_OSPIM_IOPORT_1_LOW;
  sOspiManagerCfg.IOHighPort = HAL_OSPIM_IOPORT_1_HIGH;
  if (HAL_OSPIM_Config(&hospi1, &sOspiManagerCfg, HAL_OSPI_TIMEOUT_DEFAULT_VALUE) != HAL_OK)
  {
    Error_Handler();
  }
  /* USER CODE BEGIN OCTOSPI1_Init 2 */
	HAL_OSPI_DeInit(&hospi1);
	ospi_nor_int.InterfaceMode = BSP_OSPI_NOR_OPI_MODE;
	ospi_nor_int.TransferRate = BSP_OSPI_NOR_DTR_TRANSFER;
	BSP_OSPI_NOR_DeInit(0);
	if (BSP_OSPI_NOR_Init(0, &ospi_nor_int) != BSP_ERROR_NONE)
	{
		Error_Handler();
	}
	if (BSP_OSPI_NOR_EnableMemoryMappedMode(0) != BSP_ERROR_NONE)
	{
		Error_Handler();
	}
  /* USER CODE END OCTOSPI1_Init 2 */

}

static void MX_OCTOSPI2_Init(void)
{

  /* USER CODE BEGIN OCTOSPI2_Init 0 */
	BSP_OSPI_RAM_Init_t ospi_ram_init;
  /* USER CODE END OCTOSPI2_Init 0 */

  OSPIM_CfgTypeDef sOspiManagerCfg = {0};
  OSPI_HyperbusCfgTypeDef sHyperBusCfg = {0};

  /* USER CODE BEGIN OCTOSPI2_Init 1 */
	OSPI_HyperbusCmdTypeDef sCommand =
	{ 0 };
	OSPI_MemoryMappedTypeDef sMemMappedCfg =
	{ 0 };
  /* USER CODE END OCTOSPI2_Init 1 */
  /* OCTOSPI2 parameter configuration*/
  hospi2.Instance = OCTOSPI2;
  hospi2.Init.FifoThreshold = 4;
  hospi2.Init.DualQuad = HAL_OSPI_DUALQUAD_DISABLE;
  hospi2.Init.MemoryType = HAL_OSPI_MEMTYPE_HYPERBUS;
  hospi2.Init.DeviceSize = 24;
  hospi2.Init.ChipSelectHighTime = 4;
  hospi2.Init.FreeRunningClock = HAL_OSPI_FREERUNCLK_DISABLE;
  hospi2.Init.ClockMode = HAL_OSPI_CLOCK_MODE_0;
  hospi2.Init.WrapSize = HAL_OSPI_WRAP_NOT_SUPPORTED;
  hospi2.Init.ClockPrescaler = 2;
  hospi2.Init.SampleShifting = HAL_OSPI_SAMPLE_SHIFTING_NONE;
  hospi2.Init.DelayHoldQuarterCycle = HAL_OSPI_DHQC_ENABLE;
  hospi2.Init.ChipSelectBoundary = 23;
  hospi2.Init.DelayBlockBypass = HAL_OSPI_DELAY_BLOCK_USED;
  hospi2.Init.MaxTran = 0;
  hospi2.Init.Refresh = 400;
  if (HAL_OSPI_Init(&hospi2) != HAL_OK)
  {
    Error_Handler();
  }
  sOspiManagerCfg.ClkPort = 2;
  sOspiManagerCfg.DQSPort = 2;
  sOspiManagerCfg.NCSPort = 2;
  sOspiManagerCfg.IOLowPort = HAL_OSPIM_IOPORT_2_LOW;
  sOspiManagerCfg.IOHighPort = HAL_OSPIM_IOPORT_2_HIGH;
  if (HAL_OSPIM_Config(&hospi2, &sOspiManagerCfg, HAL_OSPI_TIMEOUT_DEFAULT_VALUE) != HAL_OK)
  {
    Error_Handler();
  }
  sHyperBusCfg.RWRecoveryTime = 3;
  sHyperBusCfg.AccessTime = 6;
  sHyperBusCfg.WriteZeroLatency = HAL_OSPI_LATENCY_ON_WRITE;
  sHyperBusCfg.LatencyMode = HAL_OSPI_FIXED_LATENCY;
  if (HAL_OSPI_HyperbusCfg(&hospi2, &sHyperBusCfg, HAL_OSPI_TIMEOUT_DEFAULT_VALUE) != HAL_OK)
  {
    Error_Handler();
  }
  /* USER CODE BEGIN OCTOSPI2_Init 2 */
	sCommand.AddressSpace = HAL_OSPI_MEMORY_ADDRESS_SPACE;
	sCommand.AddressSize = HAL_OSPI_ADDRESS_32_BITS;
	sCommand.DQSMode = HAL_OSPI_DQS_ENABLE;
	sCommand.Address = 0;
	sCommand.NbData = 1;

	if (HAL_OSPI_HyperbusCmd(&hospi2, &sCommand, HAL_OSPI_TIMEOUT_DEFAULT_VALUE)
			!= HAL_OK)
	{
		Error_Handler();
	}

	sMemMappedCfg.TimeOutActivation = HAL_OSPI_TIMEOUT_COUNTER_DISABLE;

	if (HAL_OSPI_MemoryMapped(&hospi2, &sMemMappedCfg) != HAL_OK)
	{
		Error_Handler();
	}
  /* USER CODE END OCTOSPI2_Init 2 */

}

static void MX_TIM1_Init(void)
{

  TIM_SlaveConfigTypeDef sSlaveConfig = {0};
  TIM_MasterConfigTypeDef sMasterConfig = {0};

  htim1.Instance = TIM1;
  htim1.Init.Prescaler = 0;
  htim1.Init.CounterMode = TIM_COUNTERMODE_UP;
  htim1.Init.Period = 65535;
  htim1.Init.ClockDivision = TIM_CLOCKDIVISION_DIV1;
  htim1.Init.RepetitionCounter = 0;
  htim1.Init.AutoReloadPreload = TIM_AUTORELOAD_PRELOAD_DISABLE;
  if (HAL_TIM_Base_Init(&htim1) != HAL_OK)
  {
    Error_Handler();
  }
  sSlaveConfig.SlaveMode = TIM_SLAVEMODE_DISABLE;
  sSlaveConfig.InputTrigger = TIM_TS_ITR0;
  if (HAL_TIM_SlaveConfigSynchro(&htim1, &sSlaveConfig) != HAL_OK)
  {
    Error_Handler();
  }
  sMasterConfig.MasterOutputTrigger = TIM_TRGO_RESET;
  sMasterConfig.MasterOutputTrigger2 = TIM_TRGO2_RESET;
  sMasterConfig.MasterSlaveMode = TIM_MASTERSLAVEMODE_DISABLE;
  if (HAL_TIMEx_MasterConfigSynchronization(&htim1, &sMasterConfig) != HAL_OK)
  {
    Error_Handler();
  }

}

static void MX_TIM23_Init(void)
{

  TIM_Encoder_InitTypeDef sConfig = {0};
  TIM_MasterConfigTypeDef sMasterConfig = {0};

  htim23.Instance = TIM23;
  htim23.Init.Prescaler = 0;
  htim23.Init.CounterMode = TIM_COUNTERMODE_UP;
  htim23.Init.Period = 4294967295;
  htim23.Init.ClockDivision = TIM_CLOCKDIVISION_DIV1;
  htim23.Init.AutoReloadPreload = TIM_AUTORELOAD_PRELOAD_DISABLE;
  sConfig.EncoderMode = TIM_ENCODERMODE_TI1;
  sConfig.IC1Polarity = TIM_ICPOLARITY_RISING;
  sConfig.IC1Selection = TIM_ICSELECTION_DIRECTTI;
  sConfig.IC1Prescaler = TIM_ICPSC_DIV1;
  sConfig.IC1Filter = 0;
  sConfig.IC2Polarity = TIM_ICPOLARITY_RISING;
  sConfig.IC2Selection = TIM_ICSELECTION_DIRECTTI;
  sConfig.IC2Prescaler = TIM_ICPSC_DIV1;
  sConfig.IC2Filter = 0;
  if (HAL_TIM_Encoder_Init(&htim23, &sConfig) != HAL_OK)
  {
    Error_Handler();
  }
  sMasterConfig.MasterOutputTrigger = TIM_TRGO_RESET;
  sMasterConfig.MasterSlaveMode = TIM_MASTERSLAVEMODE_DISABLE;
  if (HAL_TIMEx_MasterConfigSynchronization(&htim23, &sMasterConfig) != HAL_OK)
  {
    Error_Handler();
  }

}

static void MX_UART4_Init(void)
{

  huart4.Instance = UART4;
  huart4.Init.BaudRate = 115200;
  huart4.Init.WordLength = UART_WORDLENGTH_8B;
  huart4.Init.StopBits = UART_STOPBITS_1;
  huart4.Init.Parity = UART_PARITY_NONE;
  huart4.Init.Mode = UART_MODE_TX_RX;
  huart4.Init.HwFlowCtl = UART_HWCONTROL_NONE;
  huart4.Init.OverSampling = UART_OVERSAMPLING_16;
  huart4.Init.OneBitSampling = UART_ONE_BIT_SAMPLE_DISABLE;
  huart4.Init.ClockPrescaler = UART_PRESCALER_DIV1;
  huart4.AdvancedInit.AdvFeatureInit = UART_ADVFEATURE_NO_INIT;
  if (HAL_UART_Init(&huart4) != HAL_OK)
  {
    Error_Handler();
  }
  if (HAL_UARTEx_SetTxFifoThreshold(&huart4, UART_TXFIFO_THRESHOLD_1_8) != HAL_OK)
  {
    Error_Handler();
  }
  if (HAL_UARTEx_SetRxFifoThreshold(&huart4, UART_RXFIFO_THRESHOLD_1_8) != HAL_OK)
  {
    Error_Handler();
  }
  if (HAL_UARTEx_DisableFifoMode(&huart4) != HAL_OK)
  {
    Error_Handler();
  }

}

static void MX_GPIO_Init(void)
{
  GPIO_InitTypeDef GPIO_InitStruct = {0};

  /* GPIO Ports Clock Enable */
  __HAL_RCC_GPIOE_CLK_ENABLE();
  __HAL_RCC_GPIOF_CLK_ENABLE();
  __HAL_RCC_GPIOH_CLK_ENABLE();
  __HAL_RCC_GPIOC_CLK_ENABLE();
  __HAL_RCC_GPIOA_CLK_ENABLE();
  __HAL_RCC_GPIOB_CLK_ENABLE();
  __HAL_RCC_GPIOG_CLK_ENABLE();
  __HAL_RCC_GPIOD_CLK_ENABLE();
  __HAL_RCC_GPIOJ_CLK_ENABLE();
  __HAL_RCC_GPIOK_CLK_ENABLE();

  /*Configure GPIO pin Output Level */
  HAL_GPIO_WritePin(GPIOD, GPIO_PIN_10|GPIO_PIN_0, GPIO_PIN_RESET);

  /*Configure GPIO pin Output Level */
  HAL_GPIO_WritePin(GPIOG, GPIO_PIN_15, GPIO_PIN_RESET);

  /*Configure GPIO pins : PD10 PD0 */
  GPIO_InitStruct.Pin = GPIO_PIN_10|GPIO_PIN_0;
  GPIO_InitStruct.Mode = GPIO_MODE_OUTPUT_PP;
  GPIO_InitStruct.Pull = GPIO_NOPULL;
  GPIO_InitStruct.Speed = GPIO_SPEED_FREQ_LOW;
  HAL_GPIO_Init(GPIOD, &GPIO_InitStruct);

  /*Configure GPIO pin : PG15 */
  GPIO_InitStruct.Pin = GPIO_PIN_15;
  GPIO_InitStruct.Mode = GPIO_MODE_OUTPUT_PP;
  GPIO_InitStruct.Pull = GPIO_NOPULL;
  GPIO_InitStruct.Speed = GPIO_SPEED_FREQ_LOW;
  HAL_GPIO_Init(GPIOG, &GPIO_InitStruct);

}

void StartDefaultTask(void *argument)
{
	for (;;)
	{
		osDelay(1);
	}
}

void StartTask02(void *argument)
{
  /* USER CODE BEGIN StartTask02 */
	/* Infinite loop */
	for (;;)
	{

		if (counter < 100)
		{
			counter++;
			HAL_GPIO_WritePin(GPIOG, GPIO_PIN_15,GPIO_PIN_SET);
		}
		else
		{
			counter = 0;
			HAL_GPIO_WritePin(GPIOG, GPIO_PIN_15,GPIO_PIN_RESET);
		}

		osDelay(20);

		//read external Flash

//		for(int i = 0; i < size; i++)
//		{
//		    result[i] = externalFlash[i];
//		    //externalFlash[i]= 3;
//		    //MX25LM51245G_GetFlashInfo(&infoFlash);
//		}

	}
  /* USER CODE END StartTask02 */
}

 /* MPU Configuration */

void MPU_Config(void)
{
  MPU_Region_InitTypeDef MPU_InitStruct = {0};

  /* Disables the MPU */
  HAL_MPU_Disable();

  /** Initializes and configures the Region and the memory to be protected
  */
  MPU_InitStruct.Enable = MPU_REGION_ENABLE;
  MPU_InitStruct.Number = MPU_REGION_NUMBER0;
  MPU_InitStruct.BaseAddress = 0x24000000;
  MPU_InitStruct.Size = MPU_REGION_SIZE_512KB;
  MPU_InitStruct.SubRegionDisable = 0x0;
  MPU_InitStruct.TypeExtField = MPU_TEX_LEVEL0;
  MPU_InitStruct.AccessPermission = MPU_REGION_FULL_ACCESS;
  MPU_InitStruct.DisableExec = MPU_INSTRUCTION_ACCESS_DISABLE;
  MPU_InitStruct.IsShareable = MPU_ACCESS_NOT_SHAREABLE;
  MPU_InitStruct.IsCacheable = MPU_ACCESS_CACHEABLE;
  MPU_InitStruct.IsBufferable = MPU_ACCESS_BUFFERABLE;

  HAL_MPU_ConfigRegion(&MPU_InitStruct);

  /** Initializes and configures the Region and the memory to be protected
  */
  MPU_InitStruct.Number = MPU_REGION_NUMBER1;
  MPU_InitStruct.BaseAddress = 0x70000000;
  MPU_InitStruct.Size = MPU_REGION_SIZE_512MB;
  MPU_InitStruct.AccessPermission = MPU_REGION_NO_ACCESS;
  MPU_InitStruct.IsCacheable = MPU_ACCESS_NOT_CACHEABLE;
  MPU_InitStruct.IsBufferable = MPU_ACCESS_NOT_BUFFERABLE;

  HAL_MPU_ConfigRegion(&MPU_InitStruct);

  /** Initializes and configures the Region and the memory to be protected
  */
  MPU_InitStruct.Number = MPU_REGION_NUMBER2;
  MPU_InitStruct.Size = MPU_REGION_SIZE_8MB;
  MPU_InitStruct.AccessPermission = MPU_REGION_FULL_ACCESS;
  MPU_InitStruct.IsCacheable = MPU_ACCESS_CACHEABLE;
  MPU_InitStruct.IsBufferable = MPU_ACCESS_BUFFERABLE;

  HAL_MPU_ConfigRegion(&MPU_InitStruct);

  /** Initializes and configures the Region and the memory to be protected
  */
  MPU_InitStruct.Number = MPU_REGION_NUMBER3;
  MPU_InitStruct.BaseAddress = 0x90000000;
  MPU_InitStruct.Size = MPU_REGION_SIZE_512MB;
  MPU_InitStruct.AccessPermission = MPU_REGION_NO_ACCESS;
  MPU_InitStruct.IsCacheable = MPU_ACCESS_NOT_CACHEABLE;
  MPU_InitStruct.IsBufferable = MPU_ACCESS_NOT_BUFFERABLE;

  HAL_MPU_ConfigRegion(&MPU_InitStruct);

  /** Initializes and configures the Region and the memory to be protected
  */
  MPU_InitStruct.Number = MPU_REGION_NUMBER4;
  MPU_InitStruct.Size = MPU_REGION_SIZE_64MB;
  MPU_InitStruct.AccessPermission = MPU_REGION_FULL_ACCESS;
  MPU_InitStruct.IsCacheable = MPU_ACCESS_CACHEABLE;

  HAL_MPU_ConfigRegion(&MPU_InitStruct);
  /* Enables the MPU */
  HAL_MPU_Enable(MPU_PRIVILEGED_DEFAULT);

}

void HAL_TIM_PeriodElapsedCallback(TIM_HandleTypeDef *htim)
{
  if (htim->Instance == TIM6) {
    HAL_IncTick();
  }
}

void Error_Handler(void)
{
	__disable_irq();
	while (1)
	{
	}
}
